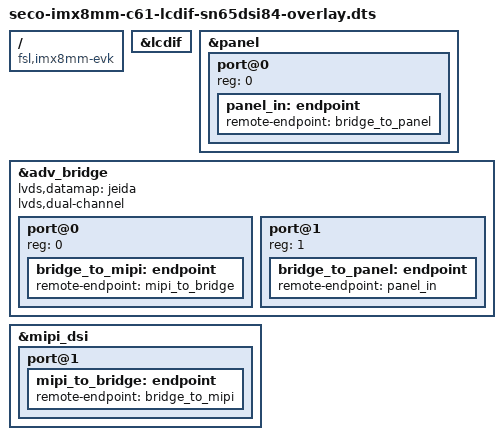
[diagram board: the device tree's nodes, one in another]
/*
 * Copyright 2017 NXP
 *
 * This program is free software; you can redistribute it and/or
 * modify it under the terms of the GNU General Public License
 * as published by the Free Software Foundation; either version 2
 * of the License, or (at your option) any later version.
 *
 * This program is distributed in the hope that it will be useful,
 * but WITHOUT ANY WARRANTY; without even the implied warranty of
 * MERCHANTABILITY or FITNESS FOR A PARTICULAR PURPOSE.  See the
 * GNU General Public License for more details.
 */


/dts-v1/;
/plugin/;

/ {
        compatible = "fsl,imx8mm-evk","seco,seco-imx8mm-c61", "fsl,imx8mm";

/*  __________________________________________________________________________
 * |                                                                          |
 * |                               WiFi                                       |
 * |__________________________________________________________________________|
 */


	fragment@1 {
                target = <&lcdif>;
                __overlay__ {
			status = "okay";
		};
        };	

	fragment@2 {
                target = <&panel>;
                __overlay__ {
			#address-cells = <1>;
			#size-cells = <0>;
			status = "okay";
                        port@0 {
                                reg = <0>;
                                panel_in: endpoint {
                                        remote-endpoint = <&bridge_to_panel>;
                                };
                        };

                 };
        };

	fragment@3 {
		target = <&adv_bridge>;
                __overlay__ {
                        #address-cells = <1>;
                        #size-cells = <0>;
                        lvds,datamap = "jeida";
                        lvds,dual-channel;
                        status = "okay";

                        port@0 {
				reg = <0>;
                                bridge_to_mipi: endpoint {
                                        remote-endpoint = <&mipi_to_bridge>;
                                };
                        };

			port@1 {
				reg = <1>;
				bridge_to_panel: endpoint {
					remote-endpoint = <&panel_in>;
				};
			};
                };
	};
	
	fragment@4 {
                target = <&mipi_dsi>;
                __overlay__ {
			status = "okay";
			port@1 {
				mipi_to_bridge: endpoint {
					remote-endpoint = <&bridge_to_mipi>;
				};
			};
		};

	};

};
